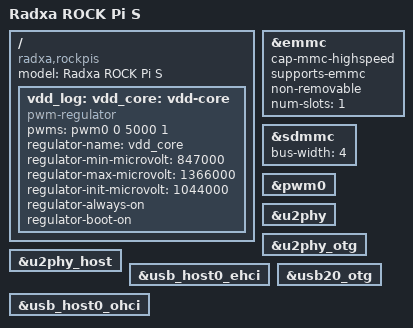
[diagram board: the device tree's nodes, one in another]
/*
 * (C) Copyright 2018 Rockchip Electronics Co., Ltd
 *
 * SPDX-License-Identifier:     GPL-2.0+
 */

/dts-v1/;
#include "rk3308.dtsi"
#include "rk3308-u-boot.dtsi"
#include <dt-bindings/input/input.h>
#include <linux/media-bus-format.h>

/ {
	model = "Radxa ROCK Pi S";
	compatible = "radxa,rockpis", "rockchip,rk3308";

	vdd_log: vdd_core: vdd-core {
		compatible = "pwm-regulator";
		pwms = <&pwm0 0 5000 1>;
		regulator-name = "vdd_core";
		regulator-min-microvolt = <847000>;
		regulator-max-microvolt = <1366000>;
		regulator-init-microvolt  = <1044000>;
		regulator-always-on;
		regulator-boot-on;
		status = "okay";
	};
};

&emmc {
	cap-mmc-highspeed;
	supports-emmc;
	non-removable;
	num-slots = <1>;
	status = "okay";
};

&sdmmc {
	bus-width = <4>;
	status = "okay";
};

&pwm0 {
	status = "okay";
};

&u2phy {
	status = "okay";
};

&u2phy_otg {
	status = "okay";
};

&u2phy_host {
	status = "okay";
};

&usb_host0_ehci {
	status = "okay";
};

&usb_host0_ohci {
	status = "okay";
};

&usb20_otg {
	status = "okay";
};

